# ipro7 register map
Vendor: intelpro; Series: BTBLE
CPU: ipro7, little endian
Registers are 32-bit, read-write, reset 0x0 unless marked. A register's access mark holds for its fields unless they carry their own. Offsets are from the block's base; [hi:lo] are bit positions; {n}, {i} and the like mark numbered series.

## TZ1
Base 0x30006000
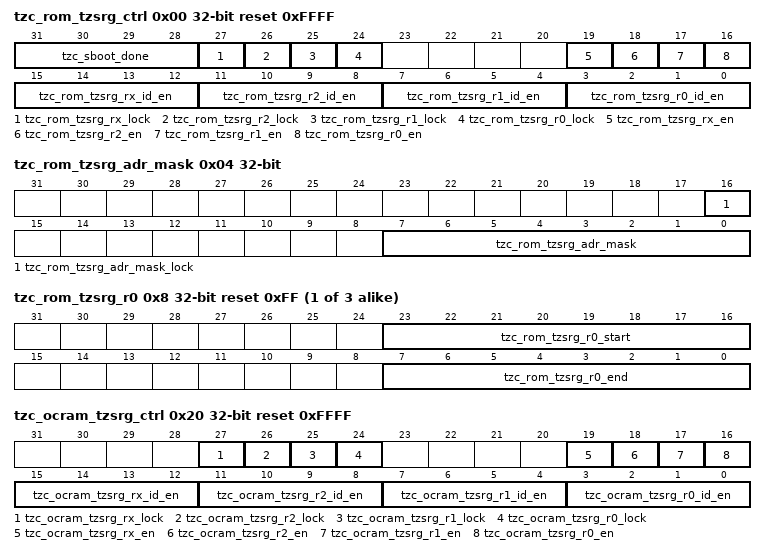
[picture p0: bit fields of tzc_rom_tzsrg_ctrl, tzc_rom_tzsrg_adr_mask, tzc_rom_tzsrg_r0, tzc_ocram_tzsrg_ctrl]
0x00 tzc_rom_tzsrg_ctrl reset 0xFFFF
  [31:28] tzc_sboot_done, [27] tzc_rom_tzsrg_rx_lock, [26] tzc_rom_tzsrg_r2_lock, [25] tzc_rom_tzsrg_r1_lock, [24] tzc_rom_tzsrg_r0_lock, [19] tzc_rom_tzsrg_rx_en, [18] tzc_rom_tzsrg_r2_en, [17] tzc_rom_tzsrg_r1_en, [16] tzc_rom_tzsrg_r0_en, [15:12] tzc_rom_tzsrg_rx_id_en, [11:8] tzc_rom_tzsrg_r2_id_en, [7:4] tzc_rom_tzsrg_r1_id_en, [3:0] tzc_rom_tzsrg_r0_id_en
0x04 tzc_rom_tzsrg_adr_mask
  [16] tzc_rom_tzsrg_adr_mask_lock — 1k byte align
  [7:0] tzc_rom_tzsrg_adr_mask — 1k byte align
{0x8+4i} tzc_rom_tzsrg_r{i} reset 0xFF (i=0..2)
  [23:16] tzc_rom_tzsrg_r{i}_start — 1k byte align
  [7:0] tzc_rom_tzsrg_r{i}_end — 1k byte align
0x20 tzc_ocram_tzsrg_ctrl reset 0xFFFF
  [27] tzc_ocram_tzsrg_rx_lock, [26] tzc_ocram_tzsrg_r2_lock, [25] tzc_ocram_tzsrg_r1_lock, [24] tzc_ocram_tzsrg_r0_lock, [19] tzc_ocram_tzsrg_rx_en, [18] tzc_ocram_tzsrg_r2_en, [17] tzc_ocram_tzsrg_r1_en, [16] tzc_ocram_tzsrg_r0_en, [15:12] tzc_ocram_tzsrg_rx_id_en, [11:8] tzc_ocram_tzsrg_r2_id_en, [7:4] tzc_ocram_tzsrg_r1_id_en, [3:0] tzc_ocram_tzsrg_r0_id_en
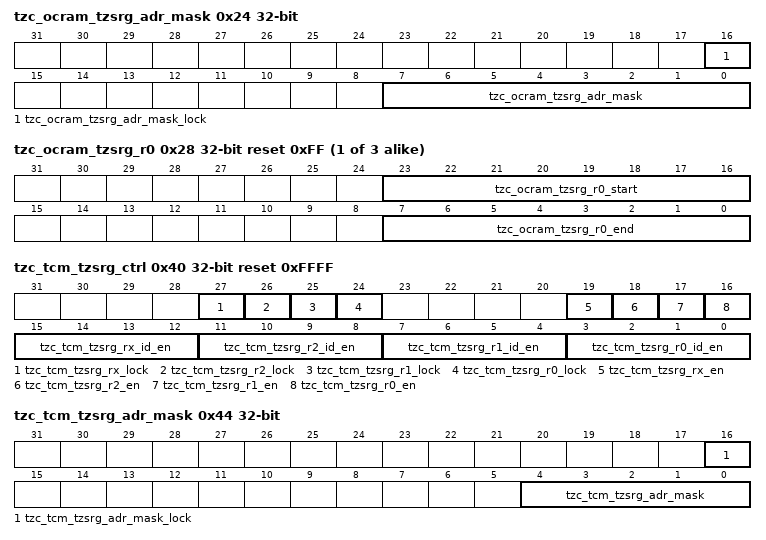
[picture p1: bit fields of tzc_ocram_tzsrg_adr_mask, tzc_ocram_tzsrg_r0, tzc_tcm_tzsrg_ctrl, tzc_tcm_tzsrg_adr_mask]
0x24 tzc_ocram_tzsrg_adr_mask
  [16] tzc_ocram_tzsrg_adr_mask_lock — 1k byte align
  [7:0] tzc_ocram_tzsrg_adr_mask — 1k byte align
{0x28+4i} tzc_ocram_tzsrg_r{i} reset 0xFF (i=0..2)
  [23:16] tzc_ocram_tzsrg_r{i}_start — 1k byte align
  [7:0] tzc_ocram_tzsrg_r{i}_end — 1k byte align
0x40 tzc_tcm_tzsrg_ctrl reset 0xFFFF
  [27] tzc_tcm_tzsrg_rx_lock, [26] tzc_tcm_tzsrg_r2_lock, [25] tzc_tcm_tzsrg_r1_lock, [24] tzc_tcm_tzsrg_r0_lock, [19] tzc_tcm_tzsrg_rx_en, [18] tzc_tcm_tzsrg_r2_en, [17] tzc_tcm_tzsrg_r1_en, [16] tzc_tcm_tzsrg_r0_en, [15:12] tzc_tcm_tzsrg_rx_id_en, [11:8] tzc_tcm_tzsrg_r2_id_en, [7:4] tzc_tcm_tzsrg_r1_id_en, [3:0] tzc_tcm_tzsrg_r0_id_en
0x44 tzc_tcm_tzsrg_adr_mask
  [16] tzc_tcm_tzsrg_adr_mask_lock — 1k byte align
  [4:0] tzc_tcm_tzsrg_adr_mask — 1k byte align
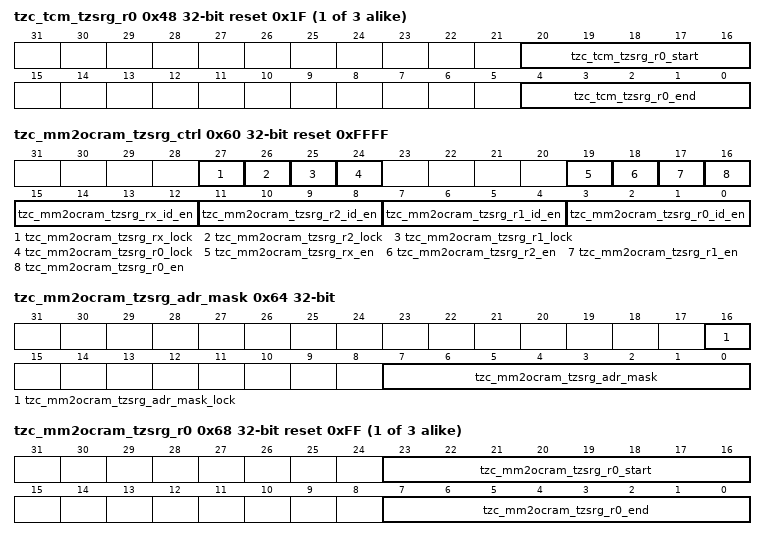
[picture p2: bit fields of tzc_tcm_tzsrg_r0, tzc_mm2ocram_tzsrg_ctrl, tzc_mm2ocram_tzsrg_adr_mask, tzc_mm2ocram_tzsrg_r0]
{0x48+4i} tzc_tcm_tzsrg_r{i} reset 0x1F (i=0..2)
  [20:16] tzc_tcm_tzsrg_r{i}_start — 1k byte align
  [4:0] tzc_tcm_tzsrg_r{i}_end — 1k byte align
0x60 tzc_mm2ocram_tzsrg_ctrl reset 0xFFFF
  [27] tzc_mm2ocram_tzsrg_rx_lock, [26] tzc_mm2ocram_tzsrg_r2_lock, [25] tzc_mm2ocram_tzsrg_r1_lock, [24] tzc_mm2ocram_tzsrg_r0_lock, [19] tzc_mm2ocram_tzsrg_rx_en, [18] tzc_mm2ocram_tzsrg_r2_en, [17] tzc_mm2ocram_tzsrg_r1_en, [16] tzc_mm2ocram_tzsrg_r0_en, [15:12] tzc_mm2ocram_tzsrg_rx_id_en, [11:8] tzc_mm2ocram_tzsrg_r2_id_en, [7:4] tzc_mm2ocram_tzsrg_r1_id_en, [3:0] tzc_mm2ocram_tzsrg_r0_id_en
0x64 tzc_mm2ocram_tzsrg_adr_mask
  [16] tzc_mm2ocram_tzsrg_adr_mask_lock — 1k byte align
  [7:0] tzc_mm2ocram_tzsrg_adr_mask — 1k byte align
{0x68+4i} tzc_mm2ocram_tzsrg_r{i} reset 0xFF (i=0..2)
  [23:16] tzc_mm2ocram_tzsrg_r{i}_start — 1k byte align
  [7:0] tzc_mm2ocram_tzsrg_r{i}_end — 1k byte align
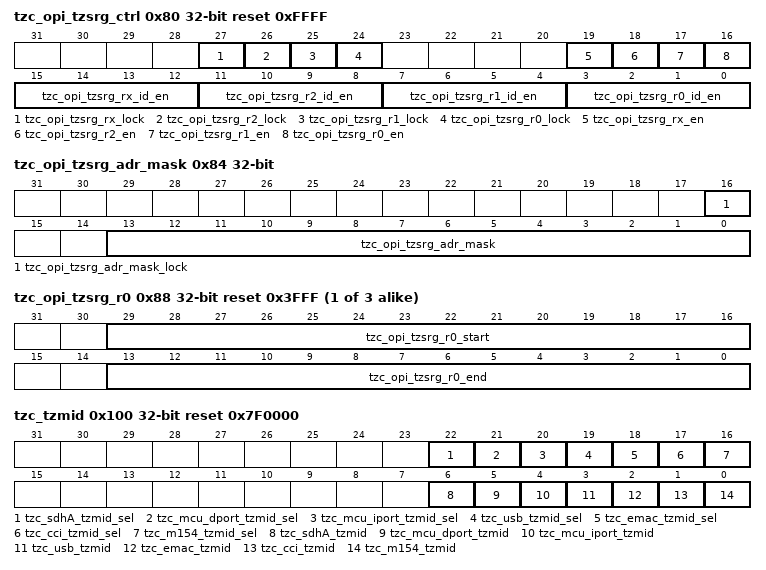
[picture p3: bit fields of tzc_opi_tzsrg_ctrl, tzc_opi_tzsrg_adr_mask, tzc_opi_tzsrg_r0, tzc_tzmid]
0x80 tzc_opi_tzsrg_ctrl reset 0xFFFF
  [27] tzc_opi_tzsrg_rx_lock, [26] tzc_opi_tzsrg_r2_lock, [25] tzc_opi_tzsrg_r1_lock, [24] tzc_opi_tzsrg_r0_lock, [19] tzc_opi_tzsrg_rx_en, [18] tzc_opi_tzsrg_r2_en, [17] tzc_opi_tzsrg_r1_en, [16] tzc_opi_tzsrg_r0_en, [15:12] tzc_opi_tzsrg_rx_id_en, [11:8] tzc_opi_tzsrg_r2_id_en, [7:4] tzc_opi_tzsrg_r1_id_en, [3:0] tzc_opi_tzsrg_r0_id_en
0x84 tzc_opi_tzsrg_adr_mask
  [16] tzc_opi_tzsrg_adr_mask_lock — 1k byte align
  [13:0] tzc_opi_tzsrg_adr_mask — 1k byte align
{0x88+4i} tzc_opi_tzsrg_r{i} reset 0x3FFF (i=0..2)
  [29:16] tzc_opi_tzsrg_r{i}_start — 1k byte align
  [13:0] tzc_opi_tzsrg_r{i}_end — 1k byte align
0x100 tzc_tzmid reset 0x7F0000
  [22] tzc_sdhA_tzmid_sel, [21] tzc_mcu_dport_tzmid_sel, [20] tzc_mcu_iport_tzmid_sel, [19] tzc_usb_tzmid_sel, [18] tzc_emac_tzmid_sel, [17] tzc_cci_tzmid_sel, [16] tzc_m154_tzmid_sel, [6] tzc_sdhA_tzmid, [5] tzc_mcu_dport_tzmid, [4] tzc_mcu_iport_tzmid, [3] tzc_usb_tzmid, [2] tzc_emac_tzmid, [1] tzc_cci_tzmid, [0] tzc_m154_tzmid
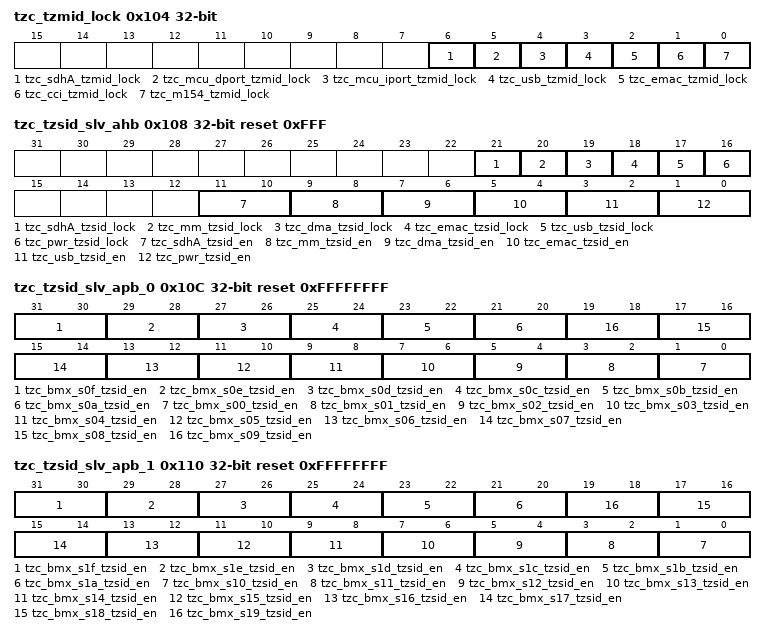
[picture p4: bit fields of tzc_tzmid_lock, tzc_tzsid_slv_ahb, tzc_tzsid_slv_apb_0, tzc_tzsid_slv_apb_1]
0x104 tzc_tzmid_lock
  [6] tzc_sdhA_tzmid_lock, [5] tzc_mcu_dport_tzmid_lock, [4] tzc_mcu_iport_tzmid_lock, [3] tzc_usb_tzmid_lock, [2] tzc_emac_tzmid_lock, [1] tzc_cci_tzmid_lock, [0] tzc_m154_tzmid_lock
0x108 tzc_tzsid_slv_ahb reset 0xFFF
  [21] tzc_sdhA_tzsid_lock — SDH
  [20] tzc_mm_tzsid_lock — MM
  [19] tzc_dma_tzsid_lock — DMA
  [18] tzc_emac_tzsid_lock — EMAC
  [17] tzc_usb_tzsid_lock — USB
  [16] tzc_pwr_tzsid_lock — HBN/PDS
  [11:10] tzc_sdhA_tzsid_en — SDH
  [9:8] tzc_mm_tzsid_en — MM
  [7:6] tzc_dma_tzsid_en — DMA
  [5:4] tzc_emac_tzsid_en — EMAC
  [3:2] tzc_usb_tzsid_en — USB
  [1:0] tzc_pwr_tzsid_en — HBN/PDS
0x10C tzc_tzsid_slv_apb_0 reset 0xFFFFFFFF
  [31:30] tzc_bmx_s0f_tzsid_en, [29:28] tzc_bmx_s0e_tzsid_en, [27:26] tzc_bmx_s0d_tzsid_en, [25:24] tzc_bmx_s0c_tzsid_en, [23:22] tzc_bmx_s0b_tzsid_en, [21:20] tzc_bmx_s0a_tzsid_en, [2n+1:2n] tzc_bmx_s{n:02}_tzsid_en (n=0..9)
0x110 tzc_tzsid_slv_apb_1 reset 0xFFFFFFFF
  [31:30] tzc_bmx_s1f_tzsid_en, [29:28] tzc_bmx_s1e_tzsid_en, [27:26] tzc_bmx_s1d_tzsid_en, [25:24] tzc_bmx_s1c_tzsid_en, [23:22] tzc_bmx_s1b_tzsid_en, [21:20] tzc_bmx_s1a_tzsid_en, [2n-19:2n-20] tzc_bmx_s{n}_tzsid_en (n=10..19)
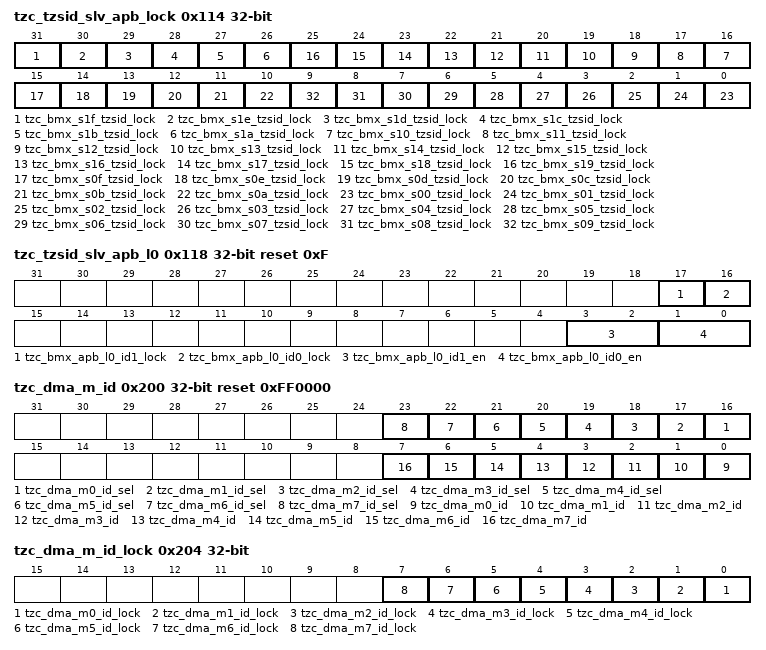
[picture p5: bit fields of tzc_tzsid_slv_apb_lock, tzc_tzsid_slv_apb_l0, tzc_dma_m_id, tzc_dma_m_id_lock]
0x114 tzc_tzsid_slv_apb_lock
  [31] tzc_bmx_s1f_tzsid_lock, [30] tzc_bmx_s1e_tzsid_lock, [29] tzc_bmx_s1d_tzsid_lock, [28] tzc_bmx_s1c_tzsid_lock, [27] tzc_bmx_s1b_tzsid_lock, [26] tzc_bmx_s1a_tzsid_lock, [n+6] tzc_bmx_s{n}_tzsid_lock (n=10..19), [15] tzc_bmx_s0f_tzsid_lock, [14] tzc_bmx_s0e_tzsid_lock, [13] tzc_bmx_s0d_tzsid_lock, [12] tzc_bmx_s0c_tzsid_lock, [11] tzc_bmx_s0b_tzsid_lock, [10] tzc_bmx_s0a_tzsid_lock, [n] tzc_bmx_s{n:02}_tzsid_lock (n=0..9)
0x118 tzc_tzsid_slv_apb_l0 reset 0xF
  [17] tzc_bmx_apb_l0_id1_lock, [16] tzc_bmx_apb_l0_id0_lock, [3:2] tzc_bmx_apb_l0_id1_en, [1:0] tzc_bmx_apb_l0_id0_en
0x200 tzc_dma_m_id reset 0xFF0000
  [n+16] tzc_dma_m{n}_id_sel (n=0..7), [n] tzc_dma_m{n}_id (n=0..7)
0x204 tzc_dma_m_id_lock
  [n] tzc_dma_m{n}_id_lock (n=0..7)
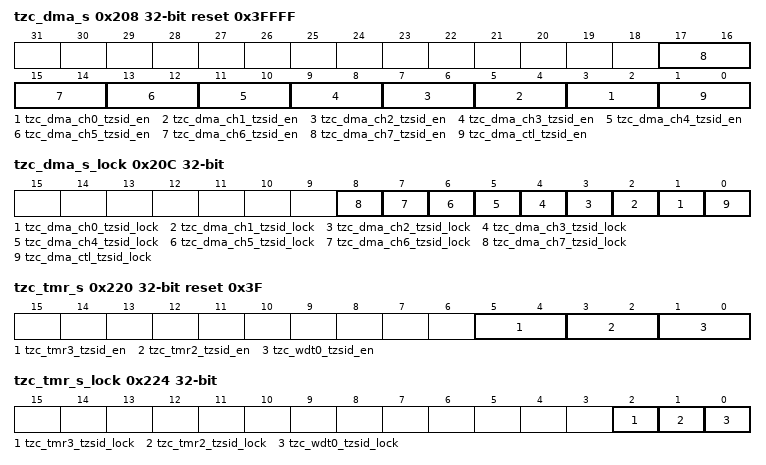
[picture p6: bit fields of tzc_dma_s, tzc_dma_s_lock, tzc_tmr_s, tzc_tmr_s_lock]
0x208 tzc_dma_s reset 0x3FFFF
  [2n+3:2n+2] tzc_dma_ch{n}_tzsid_en (n=0..7), [1:0] tzc_dma_ctl_tzsid_en
0x20C tzc_dma_s_lock
  [n+1] tzc_dma_ch{n}_tzsid_lock (n=0..7), [0] tzc_dma_ctl_tzsid_lock
0x220 tzc_tmr_s reset 0x3F
  [5:4] tzc_tmr3_tzsid_en, [3:2] tzc_tmr2_tzsid_en, [1:0] tzc_wdt0_tzsid_en
0x224 tzc_tmr_s_lock
  [2] tzc_tmr3_tzsid_lock, [1] tzc_tmr2_tzsid_lock, [0] tzc_wdt0_tzsid_lock
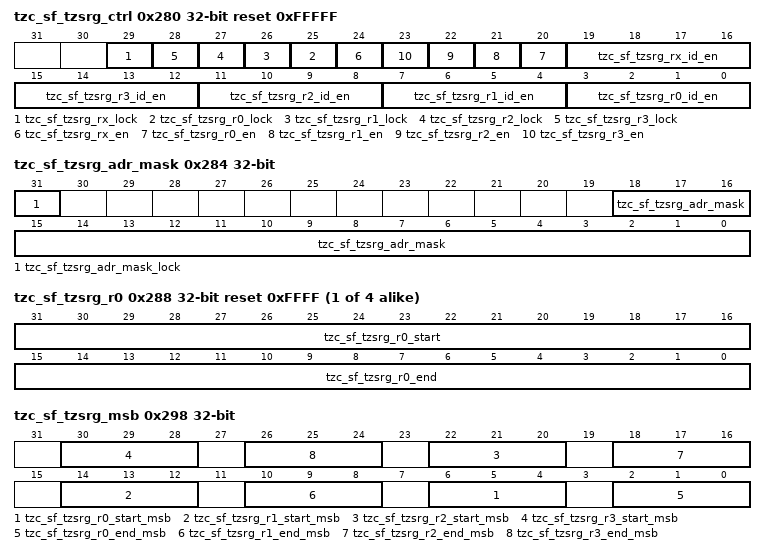
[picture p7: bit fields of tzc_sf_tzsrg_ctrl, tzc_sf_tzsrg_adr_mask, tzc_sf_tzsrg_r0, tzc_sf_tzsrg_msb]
0x280 tzc_sf_tzsrg_ctrl reset 0xFFFFF
  [29] tzc_sf_tzsrg_rx_lock
  [n+25] tzc_sf_tzsrg_r{n}_lock (n=0..3)
  [24] tzc_sf_tzsrg_rx_en
  [n+20] tzc_sf_tzsrg_r{n}_en (n=0..3)
  [19:16] tzc_sf_tzsrg_rx_id_en — tzsrg not in range r0~r3
  [4n+3:4n] tzc_sf_tzsrg_r{n}_id_en (n=0..3) — id_en[0]:id0 instruction id_en[1]:id0 data id_en[2]:id1 instruction id_en[3]:id1 data
0x284 tzc_sf_tzsrg_adr_mask
  [31] tzc_sf_tzsrg_adr_mask_lock — 1k byte align
  [18:0] tzc_sf_tzsrg_adr_mask — 1k byte align
{0x288+4i} tzc_sf_tzsrg_r{i} reset 0xFFFF (i=0..3)
  [31:16] tzc_sf_tzsrg_r{i}_start — 1k byte align
  [15:0] tzc_sf_tzsrg_r{i}_end — 1k byte align
0x298 tzc_sf_tzsrg_msb
  [8n+6:8n+4] tzc_sf_tzsrg_r{n}_start_msb (n=0..3) — 1k byte align
  [8n+2:8n] tzc_sf_tzsrg_r{n}_end_msb (n=0..3) — 1k byte align
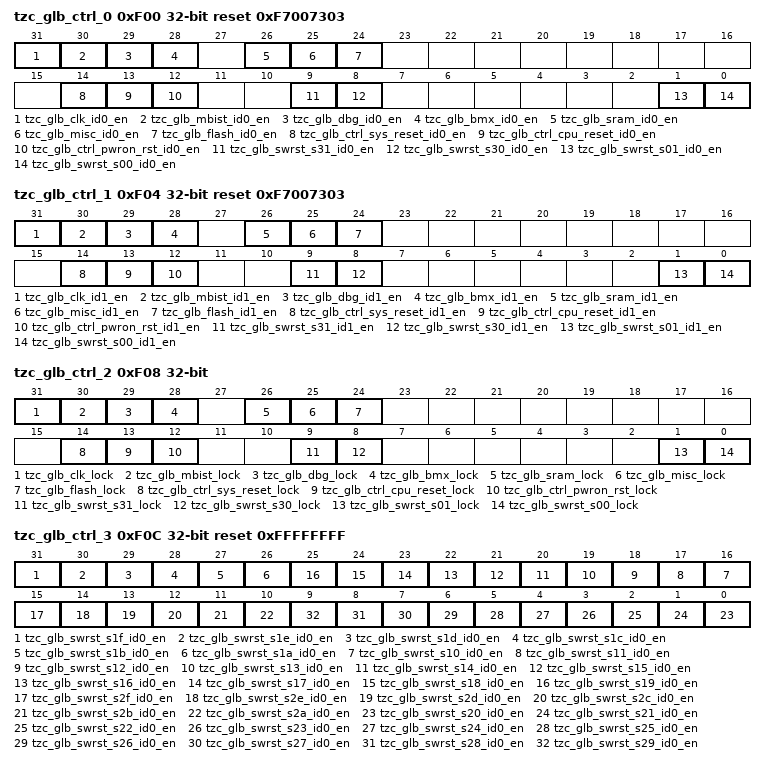
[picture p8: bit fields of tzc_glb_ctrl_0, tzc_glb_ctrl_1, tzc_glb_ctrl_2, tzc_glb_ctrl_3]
0xF00 tzc_glb_ctrl_0 reset 0xF7007303
  [31] tzc_glb_clk_id0_en, [30] tzc_glb_mbist_id0_en, [29] tzc_glb_dbg_id0_en, [28] tzc_glb_bmx_id0_en, [26] tzc_glb_sram_id0_en, [25] tzc_glb_misc_id0_en, [24] tzc_glb_flash_id0_en, [14] tzc_glb_ctrl_sys_reset_id0_en, [13] tzc_glb_ctrl_cpu_reset_id0_en, [12] tzc_glb_ctrl_pwron_rst_id0_en, [9] tzc_glb_swrst_s31_id0_en, [8] tzc_glb_swrst_s30_id0_en, [1] tzc_glb_swrst_s01_id0_en, [0] tzc_glb_swrst_s00_id0_en
0xF04 tzc_glb_ctrl_1 reset 0xF7007303
  [31] tzc_glb_clk_id1_en, [30] tzc_glb_mbist_id1_en, [29] tzc_glb_dbg_id1_en, [28] tzc_glb_bmx_id1_en, [26] tzc_glb_sram_id1_en, [25] tzc_glb_misc_id1_en, [24] tzc_glb_flash_id1_en, [14] tzc_glb_ctrl_sys_reset_id1_en, [13] tzc_glb_ctrl_cpu_reset_id1_en, [12] tzc_glb_ctrl_pwron_rst_id1_en, [9] tzc_glb_swrst_s31_id1_en, [8] tzc_glb_swrst_s30_id1_en, [1] tzc_glb_swrst_s01_id1_en, [0] tzc_glb_swrst_s00_id1_en
0xF08 tzc_glb_ctrl_2
  [31] tzc_glb_clk_lock, [30] tzc_glb_mbist_lock, [29] tzc_glb_dbg_lock, [28] tzc_glb_bmx_lock, [26] tzc_glb_sram_lock, [25] tzc_glb_misc_lock, [24] tzc_glb_flash_lock, [14] tzc_glb_ctrl_sys_reset_lock, [13] tzc_glb_ctrl_cpu_reset_lock, [12] tzc_glb_ctrl_pwron_rst_lock, [9] tzc_glb_swrst_s31_lock, [8] tzc_glb_swrst_s30_lock, [1] tzc_glb_swrst_s01_lock, [0] tzc_glb_swrst_s00_lock
0xF0C tzc_glb_ctrl_3 reset 0xFFFFFFFF
  [31] tzc_glb_swrst_s1f_id0_en, [30] tzc_glb_swrst_s1e_id0_en, [29] tzc_glb_swrst_s1d_id0_en, [28] tzc_glb_swrst_s1c_id0_en, [27] tzc_glb_swrst_s1b_id0_en, [26] tzc_glb_swrst_s1a_id0_en, [n+6] tzc_glb_swrst_s{n}_id0_en (n=10..19), [15] tzc_glb_swrst_s2f_id0_en, [14] tzc_glb_swrst_s2e_id0_en, [13] tzc_glb_swrst_s2d_id0_en, [12] tzc_glb_swrst_s2c_id0_en, [11] tzc_glb_swrst_s2b_id0_en, [10] tzc_glb_swrst_s2a_id0_en, [n-20] tzc_glb_swrst_s{n}_id0_en (n=20..29)
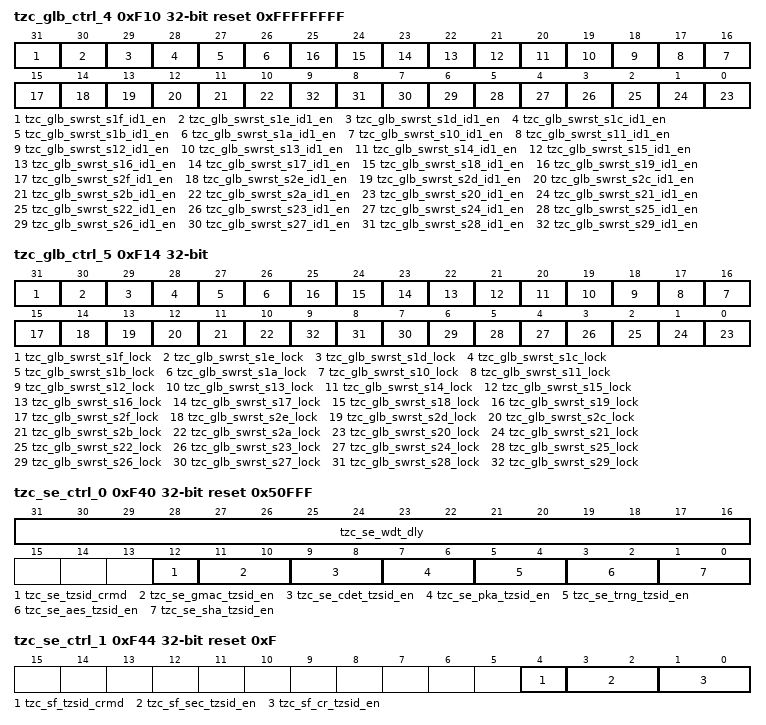
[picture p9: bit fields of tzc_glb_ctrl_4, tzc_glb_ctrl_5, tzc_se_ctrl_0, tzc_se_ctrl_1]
0xF10 tzc_glb_ctrl_4 reset 0xFFFFFFFF
  [31] tzc_glb_swrst_s1f_id1_en, [30] tzc_glb_swrst_s1e_id1_en, [29] tzc_glb_swrst_s1d_id1_en, [28] tzc_glb_swrst_s1c_id1_en, [27] tzc_glb_swrst_s1b_id1_en, [26] tzc_glb_swrst_s1a_id1_en, [n+6] tzc_glb_swrst_s{n}_id1_en (n=10..19), [15] tzc_glb_swrst_s2f_id1_en, [14] tzc_glb_swrst_s2e_id1_en, [13] tzc_glb_swrst_s2d_id1_en, [12] tzc_glb_swrst_s2c_id1_en, [11] tzc_glb_swrst_s2b_id1_en, [10] tzc_glb_swrst_s2a_id1_en, [n-20] tzc_glb_swrst_s{n}_id1_en (n=20..29)
0xF14 tzc_glb_ctrl_5
  [31] tzc_glb_swrst_s1f_lock, [30] tzc_glb_swrst_s1e_lock, [29] tzc_glb_swrst_s1d_lock, [28] tzc_glb_swrst_s1c_lock, [27] tzc_glb_swrst_s1b_lock, [26] tzc_glb_swrst_s1a_lock, [n+6] tzc_glb_swrst_s{n}_lock (n=10..19), [15] tzc_glb_swrst_s2f_lock, [14] tzc_glb_swrst_s2e_lock, [13] tzc_glb_swrst_s2d_lock, [12] tzc_glb_swrst_s2c_lock, [11] tzc_glb_swrst_s2b_lock, [10] tzc_glb_swrst_s2a_lock, [n-20] tzc_glb_swrst_s{n}_lock (n=20..29)
0xF40 tzc_se_ctrl_0 reset 0x50FFF
  [31:16] tzc_se_wdt_dly
  [12] tzc_se_tzsid_crmd — tzsid control register mode 0:arbiter mode 1:tzc control mode
  [11:10] tzc_se_gmac_tzsid_en
  [9:8] tzc_se_cdet_tzsid_en
  [7:6] tzc_se_pka_tzsid_en
  [5:4] tzc_se_trng_tzsid_en
  [3:2] tzc_se_aes_tzsid_en
  [1:0] tzc_se_sha_tzsid_en
0xF44 tzc_se_ctrl_1 reset 0xF
  [4] tzc_sf_tzsid_crmd — tzsid control register mode 0:arbiter mode 1:tzc control mode
  [3:2] tzc_sf_sec_tzsid_en — security registers tzsid enable
  [1:0] tzc_sf_cr_tzsid_en — control registers tzsid enable
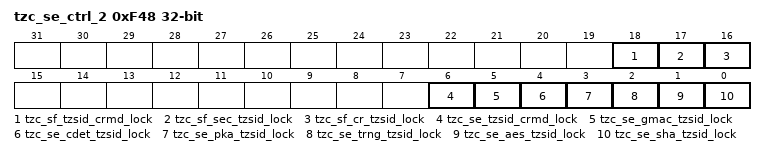
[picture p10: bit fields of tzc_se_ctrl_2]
0xF48 tzc_se_ctrl_2
  [18] tzc_sf_tzsid_crmd_lock, [17] tzc_sf_sec_tzsid_lock, [16] tzc_sf_cr_tzsid_lock, [6] tzc_se_tzsid_crmd_lock, [5] tzc_se_gmac_tzsid_lock, [4] tzc_se_cdet_tzsid_lock, [3] tzc_se_pka_tzsid_lock, [2] tzc_se_trng_tzsid_lock, [1] tzc_se_aes_tzsid_lock, [0] tzc_se_sha_tzsid_lock
